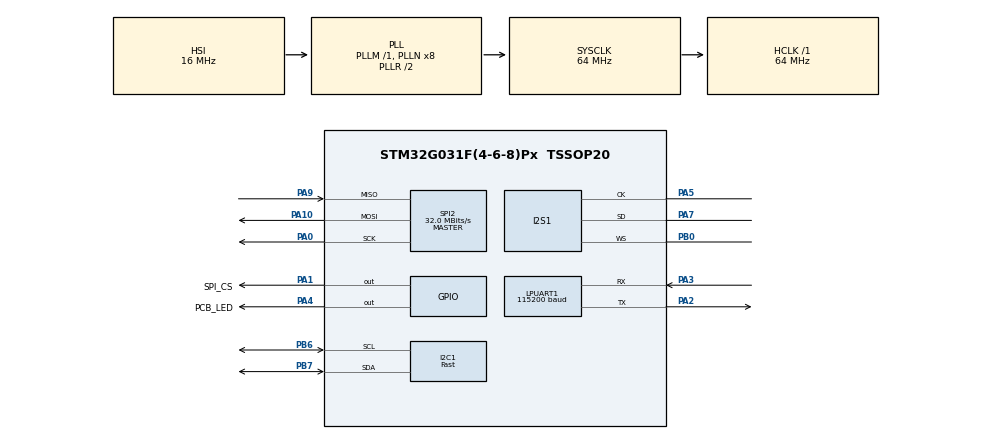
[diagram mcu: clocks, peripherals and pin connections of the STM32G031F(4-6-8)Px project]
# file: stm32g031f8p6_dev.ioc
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Dma.Request0=SPI1_TX
Dma.SPI1_TX.0.Direction=DMA_MEMORY_TO_PERIPH
Dma.SPI1_TX.0.EventEnable=DISABLE
Dma.SPI1_TX.0.Instance=DMA1_Channel1
Dma.SPI1_TX.0.MemDataAlignment=DMA_MDATAALIGN_HALFWORD
Dma.SPI1_TX.0.MemInc=DMA_MINC_ENABLE
Dma.SPI1_TX.0.Mode=DMA_CIRCULAR
Dma.SPI1_TX.0.PeriphDataAlignment=DMA_PDATAALIGN_HALFWORD
Dma.SPI1_TX.0.PeriphInc=DMA_PINC_DISABLE
Dma.SPI1_TX.0.Polarity=HAL_DMAMUX_REQ_GEN_RISING
Dma.SPI1_TX.0.Priority=DMA_PRIORITY_LOW
Dma.SPI1_TX.0.RequestNumber=1
Dma.SPI1_TX.0.SignalID=NONE
Dma.SPI1_TX.0.SyncEnable=DISABLE
Dma.SPI1_TX.0.SyncPolarity=HAL_DMAMUX_SYNC_NO_EVENT
Dma.SPI1_TX.0.SyncRequestNumber=1
Dma.SPI1_TX.0.SyncSignalID=NONE
I2C1.I2C_Speed_Mode=I2C_Fast
I2C1.Timing=0x00C12166
I2S1.AudioFreq=I2S_AUDIOFREQ_48K
I2S1.ErrorAudioFreq=-0.79 %
I2S1.FullDuplexMode=I2S_FULLDUPLEXMODE_DISABLE
I2S1.Instance=SPI$Index
I2S1.RealAudioFreq=47.619 KHz
I2S1.VirtualMode=I2S_MODE_MASTER
LPUART1.BaudRate=115200
LPUART1.WordLength=UART_WORDLENGTH_8B
Mcu.Family=STM32G0
Mcu.Name=STM32G031F(4-6-8)Px
Mcu.Package=TSSOP20
NVIC.DMA1_Channel1_IRQn=true\:0\:0\:false\:false\:true\:false\:true\:true
NVIC.I2C1_IRQn=true\:0\:0\:false\:false\:true\:true\:true\:true
NVIC.SPI2_IRQn=true\:0\:0\:false\:false\:true\:true\:true\:true
PA0.Mode=Full_Duplex_Master
PA0.Signal=SPI2_SCK
PA1.GPIO_Label=SPI_CS
PA1.GPIO_Speed=GPIO_SPEED_FREQ_VERY_HIGH
PA1.PinState=GPIO_PIN_SET
PA1.Signal=GPIO_Output
PA10\ [PA12].Mode=Full_Duplex_Master
PA10\ [PA12].Signal=SPI2_MOSI
PA13.Mode=Serial_Wire
PA13.Signal=SYS_SWDIO
PA14-BOOT0.Mode=Serial_Wire
PA14-BOOT0.Signal=SYS_SWCLK
PA14-BOOT0__PA15.StandardMode=true
PA2.Mode=Asynchronous
PA2.Signal=LPUART1_TX
PA3.Mode=Asynchronous
PA3.Signal=LPUART1_RX
PA4.GPIO_Label=PCB_LED
PA4.GPIO_Speed=GPIO_SPEED_FREQ_LOW
PA4.Signal=GPIO_Output
PA5.Mode=Half_Duplex_Master
PA5.Signal=I2S1_CK
PA7.Mode=Half_Duplex_Master
PA7.Signal=I2S1_SD
PA9\ [PA11].Mode=Full_Duplex_Master
PA9\ [PA11].Signal=SPI2_MISO
PB0.Mode=Half_Duplex_Master
PB0.Signal=I2S1_WS
PB0__PB1__PB2__PA8.StandardMode=true
PB3__PB4__PB5__PB6.StandardMode=true
PB6.Mode=I2C
PB6.Signal=I2C1_SCL
PB7.Mode=I2C
PB7.Signal=I2C1_SDA
PB7__PB8.StandardMode=true
PC14-OSC32_IN\ (PC14).Mode=LSE-External-Oscillator
PC14-OSC32_IN\ (PC14).Signal=RCC_OSC32_IN
PC14-OSC32_IN\ (PC14)__PB9.StandardMode=true
PC15-OSC32_OUT\ (PC15).Mode=LSE-External-Oscillator
PC15-OSC32_OUT\ (PC15).Signal=RCC_OSC32_OUT
ProjectManager.HeapSize=0x200
ProjectManager.StackSize=0x400
ProjectManager.TargetToolchain=CMake
RCC.ADCFreq_Value=64000000
RCC.AHBFreq_Value=64000000
RCC.CortexFreq_Value=64000000
RCC.EXTERNAL_CLOCK_VALUE=12288000
RCC.HCLKFreq_Value=64000000
RCC.HSE_VALUE=8000000
RCC.HSI_VALUE=16000000
RCC.RTCClockSelection=RCC_RTCCLKSOURCE_LSE
RCC.SYSCLKFreq_VALUE=64000000
RCC.SYSCLKSource=RCC_SYSCLKSOURCE_PLLCLK
RCC.VCOOutputFreq_Value=128000000
RTC.Format=RTC_FORMAT_BIN
RTC.Year=23
SPI2.CalculateBaudRate=32.0 MBits/s
SPI2.Direction=SPI_DIRECTION_2LINES
SPI2.Mode=SPI_MODE_MASTER
SPI2.VirtualType=VM_MASTER
VP_CRC_VS_CRC.Mode=CRC_Activate
VP_RTC_VS_RTC_Activate.Mode=RTC_Enabled
VP_RTC_VS_RTC_Calendar.Mode=RTC_Calendar
VP_SYS_VS_PINREMAP.Mode=PINREMAP
VP_SYS_VS_PINREMAP_10_12.Mode=PINREMAP_10_12
board=custom

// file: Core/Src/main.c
/* USER CODE BEGIN Header */
/**
  ******************************************************************************
  * @file           : main.c
  * @brief          : Main program body
  ******************************************************************************
  * @attention
  *
  * Copyright (c) 2026 STMicroelectronics.
  * All rights reserved.
  *
  * This software is licensed under terms that can be found in the LICENSE file
  * in the root directory of this software component.
  * If no LICENSE file comes with this software, it is provided AS-IS.
  *
  ******************************************************************************
  */
/* USER CODE END Header */
#include "main.h"
#include "crc.h"
#include "dma.h"
#include "i2c.h"
#include "i2s.h"
#include "usart.h"
#include "rtc.h"
#include "spi.h"
#include "gpio.h"

/* USER CODE BEGIN Includes */

#include "app_main.h"

/* USER CODE END Includes */

void SystemClock_Config(void);

int main(void)
{

  /* MCU Configuration--------------------------------------------------------*/

  /* Reset of all peripherals, Initializes the Flash interface and the Systick. */
  HAL_Init();

  /* Configure the system clock */
  SystemClock_Config();

  /* Initialize all configured peripherals */
  MX_GPIO_Init();
  MX_DMA_Init();
  MX_RTC_Init();
  MX_CRC_Init();
  MX_I2C1_Init();
  MX_I2S1_Init();
  MX_LPUART1_UART_Init();
  MX_SPI2_Init();
  /* USER CODE BEGIN 2 */

  app_main_init(); // アプリ初期化

  /* USER CODE END 2 */

  /* Infinite loop */
  while (1)
  {

    /* USER CODE BEGIN 3 */

    app_main(); // アプリメイン

    HAL_Delay(1000);
  }
  /* USER CODE END 3 */
}

void SystemClock_Config(void)
{
  RCC_OscInitTypeDef RCC_OscInitStruct = {0};
  RCC_ClkInitTypeDef RCC_ClkInitStruct = {0};

  /** Configure the main internal regulator output voltage
  */
  HAL_PWREx_ControlVoltageScaling(PWR_REGULATOR_VOLTAGE_SCALE1);

  /** Configure LSE Drive Capability
  */
  HAL_PWR_EnableBkUpAccess();
  __HAL_RCC_LSEDRIVE_CONFIG(RCC_LSEDRIVE_LOW);

  /** Initializes the RCC Oscillators according to the specified parameters
  * in the RCC_OscInitTypeDef structure.
  */
  RCC_OscInitStruct.OscillatorType = RCC_OSCILLATORTYPE_HSI|RCC_OSCILLATORTYPE_LSE;
  RCC_OscInitStruct.LSEState = RCC_LSE_ON;
  RCC_OscInitStruct.HSIState = RCC_HSI_ON;
  RCC_OscInitStruct.HSIDiv = RCC_HSI_DIV1;
  RCC_OscInitStruct.HSICalibrationValue = RCC_HSICALIBRATION_DEFAULT;
  RCC_OscInitStruct.PLL.PLLState = RCC_PLL_ON;
  RCC_OscInitStruct.PLL.PLLSource = RCC_PLLSOURCE_HSI;
  RCC_OscInitStruct.PLL.PLLM = RCC_PLLM_DIV1;
  RCC_OscInitStruct.PLL.PLLN = 8;
  RCC_OscInitStruct.PLL.PLLP = RCC_PLLP_DIV2;
  RCC_OscInitStruct.PLL.PLLQ = RCC_PLLQ_DIV2;
  RCC_OscInitStruct.PLL.PLLR = RCC_PLLR_DIV2;
  if (HAL_RCC_OscConfig(&RCC_OscInitStruct) != HAL_OK)
  {
    Error_Handler();
  }

  /** Initializes the CPU, AHB and APB buses clocks
  */
  RCC_ClkInitStruct.ClockType = RCC_CLOCKTYPE_HCLK|RCC_CLOCKTYPE_SYSCLK
                              |RCC_CLOCKTYPE_PCLK1;
  RCC_ClkInitStruct.SYSCLKSource = RCC_SYSCLKSOURCE_PLLCLK;
  RCC_ClkInitStruct.AHBCLKDivider = RCC_SYSCLK_DIV1;
  RCC_ClkInitStruct.APB1CLKDivider = RCC_HCLK_DIV1;

  if (HAL_RCC_ClockConfig(&RCC_ClkInitStruct, FLASH_LATENCY_2) != HAL_OK)
  {
    Error_Handler();
  }
}

void Error_Handler(void)
{
  __disable_irq();
  while (1)
  {
  }
}
